VERSION ""

NS_ :

BS_:

BU_:

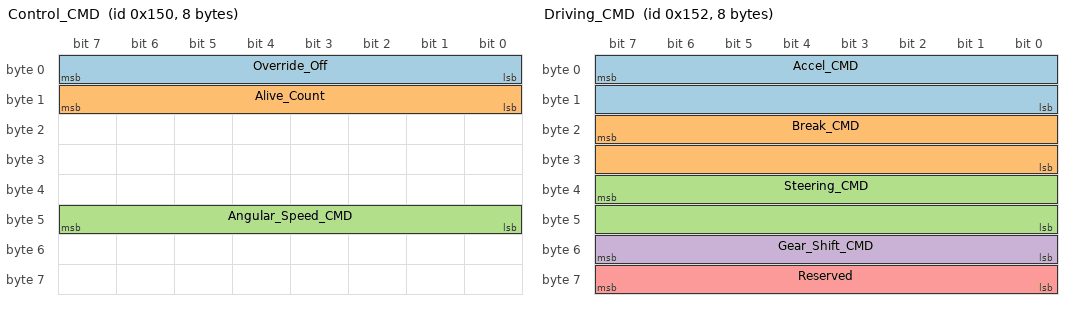
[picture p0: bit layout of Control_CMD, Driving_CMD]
BO_ 336 Control_CMD: 8 Vector__XXX
SG_ Override_Off : 7|8@0+ (1,0) [0|1] "None" Vector__XXX
SG_ Alive_Count : 15|8@0+ (1,0) [0|255] "None" Vector__XXX
SG_ Angular_Speed_CMD : 47|8@0+ (1,0) [0|255] "None" Vector__XXX

BO_ 338 Driving_CMD: 8 Vector__XXX
SG_ Accel_CMD : 7|16@0+ (1,0) [650|3400] "" Vector__XXX
SG_ Break_CMD : 23|16@0+ (1,0) [0|17000] "" Vector__XXX
SG_ Steering_CMD : 39|16@0- (1,0) [-520|520] "deg" Vector__XXX
SG_ Gear_Shift_CMD : 55|8@0+ (1,0) [0|7] "" Vector__XXX
SG_ Reserved : 63|8@0+ (1,0) [0|0] "" Vector__XXX

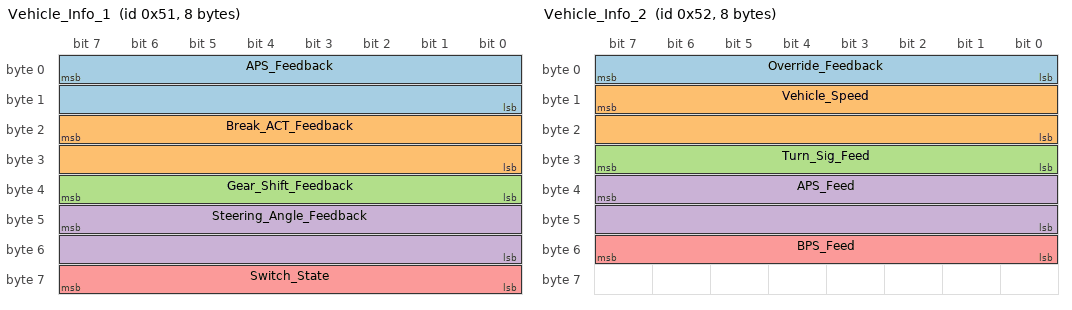
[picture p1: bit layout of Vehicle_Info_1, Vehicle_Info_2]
BO_ 81 Vehicle_Info_1: 8 Vector__XXX
SG_ APS_Feedback : 7|16@0+ (1,0) [0|3800] "" Vector__XXX
SG_ Break_ACT_Feedback : 23|16@0+ (1,0) [0|35000] "" Vector__XXX
SG_ Gear_Shift_Feedback : 39|8@0+ (1,0) [0|0] "" Vector__XXX
SG_ Steering_Angle_Feedback : 47|16@0- (1,0) [-540|540] "" Vector__XXX
SG_ Switch_State : 63|8@0+ (1,0) [0|0] "" Vector__XXX

BO_ 82 Vehicle_Info_2: 8 Vector__XXX
SG_ Override_Feedback : 7|8@0+ (1,0) [0|6] "" Vector__XXX
SG_ Vehicle_Speed : 15|16@0+ (1,0) [0|255] "km/h" Vector__XXX
SG_ Turn_Sig_Feed : 31|8@0+ (1,0) [0|0] "" Vector__XXX
SG_ APS_Feed : 39|16@0+ (1,0) [0|0] "" Vector__XXX
SG_ BPS_Feed : 55|8@0+ (1,0) [0|0] "" Vector__XXX

BO_ 83 Vehicle_Info_3: 8 Vector__XXX
SG_ RPM : 7|16@0+ (1,0) [0|0] "rpm" Vector__XXX

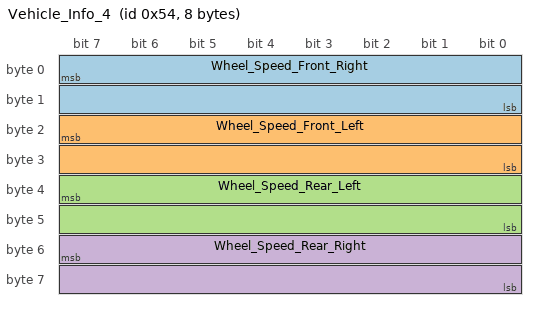
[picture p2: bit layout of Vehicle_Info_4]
BO_ 84 Vehicle_Info_4: 8 Vector__XXX
SG_ Wheel_Speed_Front_Right : 7|16@0+ (1,0) [0|255] "km/h" Vector__XXX
SG_ Wheel_Speed_Front_Left : 23|16@0+ (1,0) [0|255] "km/h" Vector__XXX
SG_ Wheel_Speed_Rear_Left : 39|16@0+ (1,0) [0|255] "km/h" Vector__XXX
SG_ Wheel_Speed_Rear_Right : 55|16@0+ (1,0) [0|255] "km/h" Vector__XXX

CM_ SG_ 336 Alive_Count "Heartbeat";
CM_ SG_ 336 Angular_Speed_CMD "steering";
CM_ SG_ 338 Accel_CMD "Accel Actuator CMD";
CM_ SG_ 338 Break_CMD "Break actuator CMD";
CM_ SG_ 338 Steering_CMD "- left + right";
CM_ SG_ 81 APS_Feedback "Accel actuator feedback";
CM_ SG_ 81 Break_ACT_Feedback "Break actuator feedback
";
CM_ SG_ 81 Gear_Shift_Feedback "Gear Feedback (OBD2)";
CM_ SG_ 81 Steering_Angle_Feedback "- left + right";
CM_ SG_ 82 Override_Feedback "Override Feedback
";
CM_ SG_ 82 Vehicle_Speed "Vehicle Speed";
CM_ SG_ 82 Turn_Sig_Feed "Lamp";
CM_ SG_ 83 RPM "Engine RPM";
CM_ SG_ 84 Wheel_Speed_Front_Right "Front Right";
CM_ SG_ 84 Wheel_Speed_Front_Left "Front Left";
CM_ SG_ 84 Wheel_Speed_Rear_Left "Rear Left";
CM_ SG_ 84 Wheel_Speed_Rear_Right "Rear Right";

VAL_ 336 Override_Off 0 "Override_On" 1 "Override_Off" ;
VAL_ 338 Gear_shift_CMD 0 "Parking" 5 "Driving" 6 "Neutral" 7 "Reverse" ;
VAL_ 81 Gear_shift_Feedback 0 "Parking" 5 "Driving" 6 "Neutral" 7 "Reverse" ;
VAL_ 81 Switch_state 0 "Manual" 1 "E-stop" 2 "Auto-standby" 4 "APM S/W On" 8 "ASM S/W On" 16 "AGM S/W On" ;
VAL_ 82 Override_feedback 0 "Manual" 1 "Auto" 2 "Steer" 3 "Accel" 4 "Brake" 5 "Sensor" 6 "E-Stop" ;
VAL_ 82 Turn_Sig_feed 0 "Lamp_Off" 1 "Left_Lamp_Open" 2 "Right_Lamp_Open" 4 "Hazard_Lamp_Open" ;
